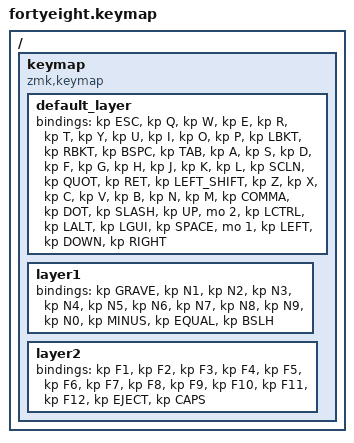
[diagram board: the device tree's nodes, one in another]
#include <behaviors.dtsi>
#include <dt-bindings/zmk/keys.h>

/ {
    keymap {
        compatible = "zmk,keymap";

        default_layer {
            bindings = <
&kp ESC         &kp Q     &kp W     &kp E      &kp R  &kp T     &kp Y     &kp U      &kp I      &kp O    &kp P      &kp LBKT  &kp RBKT  &kp BSPC
&kp TAB         &kp A     &kp S     &kp D      &kp F  &kp G     &kp H     &kp J      &kp K      &kp L    &kp SCLN   &kp QUOT  &kp RET
&kp LEFT_SHIFT  &kp Z     &kp X     &kp C      &kp V  &kp B     &kp N     &kp M      &kp COMMA  &kp DOT  &kp SLASH  &kp UP    &mo 2
&kp LCTRL       &kp LALT  &kp LGUI  &kp SPACE  &mo 1  &kp LEFT  &kp DOWN  &kp RIGHT
            >;
        };

        layer1 {
            bindings = <
&kp GRAVE  &kp N1  &kp N2  &kp N3  &kp N4  &kp N5  &kp N6  &kp N7  &kp N8  &kp N9  &kp N0  &kp MINUS  &kp EQUAL  &kp BSLH
            >;
        };

        layer2 {
            bindings = <
&kp F1  &kp F2  &kp F3  &kp F4  &kp F5  &kp F6  &kp F7  &kp F8  &kp F9  &kp F10  &kp F11  &kp F12  &kp EJECT  &kp CAPS
            >;
        };
    };
};
